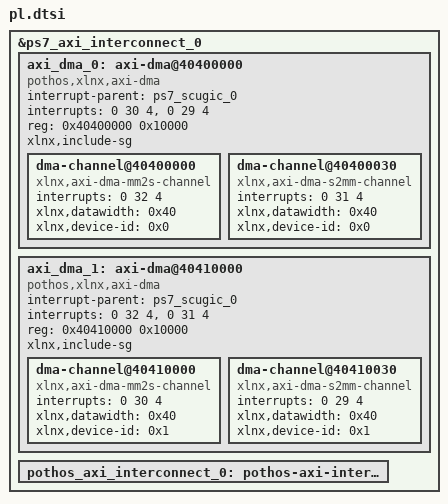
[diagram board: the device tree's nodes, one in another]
/*
 * CAUTION: This file is automatically generated by Xilinx.
 * Version:  
 * Today is: Thu Dec 11 17:20:28 2014
*/

	&ps7_axi_interconnect_0 {
		ranges;
		axi_dma_0: axi-dma@40400000 {
			compatible = "pothos,xlnx,axi-dma";
			interrupt-parent = <&ps7_scugic_0>;
			interrupts = <0 30 4>, <0 29 4>;
			reg = <0x40400000 0x10000>;
			xlnx,include-sg ;
			dma-channel@40400000 {
				compatible = "xlnx,axi-dma-mm2s-channel";
				interrupts = <0 32 4>;
				xlnx,datawidth = <0x40>;
				xlnx,device-id = <0x0>;
			} ;
			dma-channel@40400030 {
				compatible = "xlnx,axi-dma-s2mm-channel";
				interrupts = <0 31 4>;
				xlnx,datawidth = <0x40>;
				xlnx,device-id = <0x0>;
			} ;
		} ;
		axi_dma_1: axi-dma@40410000 {
			compatible = "pothos,xlnx,axi-dma";
			interrupt-parent = <&ps7_scugic_0>;
			interrupts = <0 32 4>, <0 31 4>;
			reg = <0x40410000 0x10000>;
			xlnx,include-sg ;
			dma-channel@40410000 {
				compatible = "xlnx,axi-dma-mm2s-channel";
				interrupts = <0 30 4>;
				xlnx,datawidth = <0x40>;
				xlnx,device-id = <0x1>;
			} ;
			dma-channel@40410030 {
				compatible = "xlnx,axi-dma-s2mm-channel";
				interrupts = <0 29 4>;
				xlnx,datawidth = <0x40>;
				xlnx,device-id = <0x1>;
			} ;
		} ;
		pothos_axi_interconnect_0: pothos-axi-interconnect@43c00000 {
		} ;
	} ;
